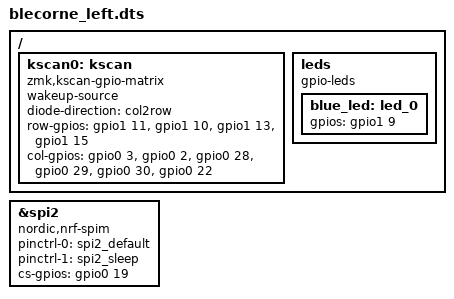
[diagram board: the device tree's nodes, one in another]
/*
* Copyright (c) 2024 Kyle Brown
* SPDX-License-Identifier: MIT
*/

#include "blecorne.dtsi"

/{
    kscan0: kscan {
        compatible = "zmk,kscan-gpio-matrix";
        wakeup-source;

        diode-direction = "col2row";
        row-gpios
            = <&gpio1 11 (GPIO_ACTIVE_HIGH | GPIO_PULL_DOWN)>
            , <&gpio1 10 (GPIO_ACTIVE_HIGH | GPIO_PULL_DOWN)>
            , <&gpio1 13 (GPIO_ACTIVE_HIGH | GPIO_PULL_DOWN)>
            , <&gpio1 15 (GPIO_ACTIVE_HIGH | GPIO_PULL_DOWN)>
            ;

        col-gpios
            = <&gpio0  3 GPIO_ACTIVE_HIGH>
            , <&gpio0 2 GPIO_ACTIVE_HIGH>
            , <&gpio0 28 GPIO_ACTIVE_HIGH>
            , <&gpio0 29 GPIO_ACTIVE_HIGH>
            , <&gpio0 30 GPIO_ACTIVE_HIGH>
            , <&gpio0 22 GPIO_ACTIVE_HIGH>
            ;
    };

    leds {
        compatible = "gpio-leds";
        blue_led: led_0 {
            gpios = <&gpio1 9 GPIO_ACTIVE_HIGH>;
        };
    };
};

nice_view_spi: &spi2 {
    status = "okay";
    compatible = "nordic,nrf-spim";
    pinctrl-0 = <&spi2_default>;
    pinctrl-1 = <&spi2_sleep>;
    pinctrl-names = "default", "sleep";
    cs-gpios = <&gpio0 19 GPIO_ACTIVE_HIGH>;
};
